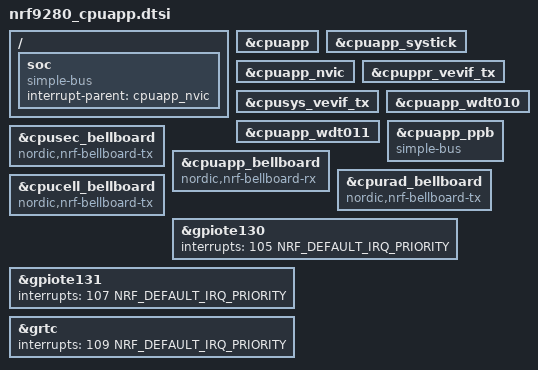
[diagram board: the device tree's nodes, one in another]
/*
 * Copyright (c) 2024 Nordic Semiconductor ASA
 *
 * SPDX-License-Identifier: Apache-2.0
 */

#include <nordic/nrf9280.dtsi>

cpu: &cpuapp {};
systick: &cpuapp_systick {};
nvic: &cpuapp_nvic {};
cpuppr_vevif: &cpuppr_vevif_tx {};
cpusys_vevif: &cpusys_vevif_tx {};
wdt010: &cpuapp_wdt010 {};
wdt011: &cpuapp_wdt011 {};

/delete-node/ &cpuppr;
/delete-node/ &cpurad;
/delete-node/ &cpurad_peripherals;
/delete-node/ &cpurad_ppb;
/delete-node/ &cpurad_ram0;

/ {
	soc {
		compatible = "simple-bus";
		interrupt-parent = <&cpuapp_nvic>;
		ranges;
	};
};

&cpuapp_ppb {
	compatible = "simple-bus";
	ranges;
};

&cpusec_bellboard {
	compatible = "nordic,nrf-bellboard-tx";
};

&cpuapp_bellboard {
	compatible = "nordic,nrf-bellboard-rx";
};

&cpurad_bellboard {
	compatible = "nordic,nrf-bellboard-tx";
};

&cpucell_bellboard {
	compatible = "nordic,nrf-bellboard-tx";
};

&gpiote130 {
	interrupts = <105 NRF_DEFAULT_IRQ_PRIORITY>;
};

&gpiote131 {
	interrupts = <107 NRF_DEFAULT_IRQ_PRIORITY>;
};

&grtc {
	interrupts = <109 NRF_DEFAULT_IRQ_PRIORITY>;
};
